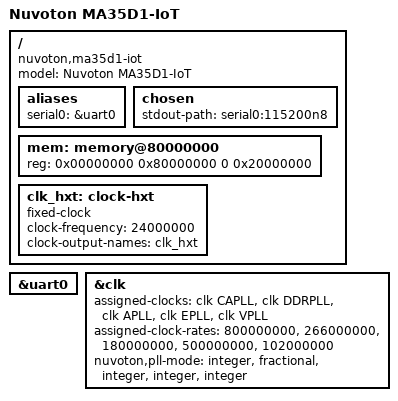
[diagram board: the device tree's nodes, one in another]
/dts-v1/;
#include "ma35d1.dtsi"
/ {
	model = "Nuvoton MA35D1-IoT";
	compatible = "nuvoton,ma35d1-iot", "nuvoton,ma35d1";
	aliases {
		serial0 = &uart0;
	};
	chosen {
		stdout-path = "serial0:115200n8";
	};
	mem: memory@80000000 {
		device_type = "memory";
		reg = <0x00000000 0x80000000 0 0x20000000>;  
	};
	clk_hxt: clock-hxt {
		compatible = "fixed-clock";
		#clock-cells = <0>;
		clock-frequency = <24000000>;
		clock-output-names = "clk_hxt";
	};
};
&uart0 {
	status = "okay";
};
&clk {
	assigned-clocks = <&clk CAPLL>,
			  <&clk DDRPLL>,
			  <&clk APLL>,
			  <&clk EPLL>,
			  <&clk VPLL>;
	assigned-clock-rates = <800000000>,
			       <266000000>,
			       <180000000>,
			       <500000000>,
			       <102000000>;
	nuvoton,pll-mode = "integer",
			   "fractional",
			   "integer",
			   "integer",
			   "integer";
};
